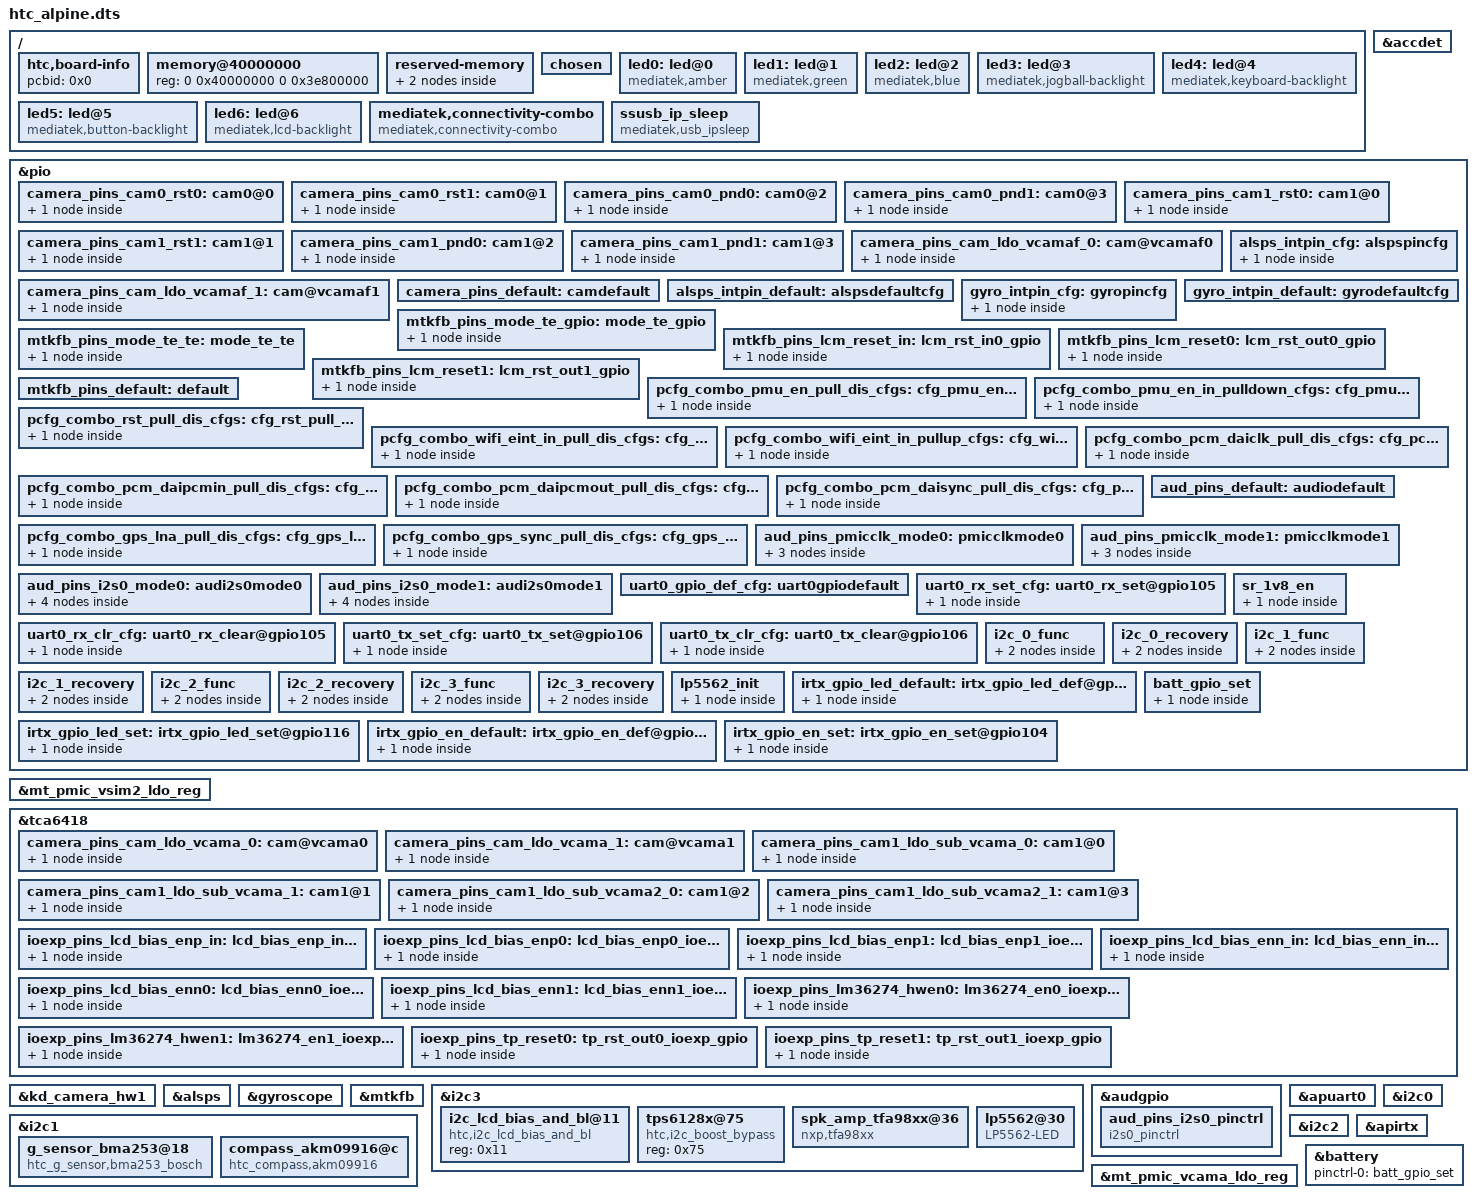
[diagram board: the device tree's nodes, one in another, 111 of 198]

/dts-v1/;

#include "mt6755.dtsi"
#include "htc_alpine/mt6755-ioexp-alpine.dtsi"
#include "htc_alpine/mt6755-usb-alpine.dtsi"
#include "htc_alpine/mt6755-key-alpine.dtsi"
#include "htc_alpine/mt6755-fp-alpine.dtsi"
#include "htc_alpine/mt6755-shub-alpine.dtsi"
#include "htc_alpine/mt6755-hallsensor-alpine-XA.dtsi"
#include "htc_alpine/mt6755-vibrator-alpine.dtsi"
#include "cust.dtsi"
#include "htc_features.dtsi"
#include "htc_alpine/mt6755-touch-alpine.dtsi"
#include "htc_alpine/mt6755-cap-alpine.dtsi"
#include "htc_alpine/mt6755-flashlight-alpine.dtsi"
#include "htc_alpine/cust_mt6755_msdc.dtsi"
#include "htc_alpine/mt6755-nfc-alpine.dtsi"
#include "htc_alpine/mt6755-audio-alpine.dtsi"

/ {
	htc,board-info {
		pcbid = <0x0>;
	};
	memory@40000000 {
		device_type = "memory";
		reg = <0 0x40000000 0 0x3e800000>;
	};
	reserved-memory {
		#address-cells = <2>;
		#size-cells = <2>;
		ranges;

		memory-ssvp-reserved-memory {
			compatible = "mediatek,memory-ssvp";
			size = <0 0x10000000>;
			alignment = <0 0x1000000>;
			alloc-ranges = <0 0x40000000 0 0xbf000000>;
		};

		reserve-memory-ccci_md3_ccif {
			compatible = "mediatek,reserve-memory-ccci_md3_ccif";
			no-map;
			size = <0 0x01000000>;
			alignment = <0 0x2000000>;
			alloc-ranges = <0 0x40000000 0 0xc0000000>;
		};
	};

	/* chosen */
	chosen {
		bootargs = "console=tty0 console=ttyMT0,921600n1 root=/dev/ram initrd=0x44000000,0x4B434E loglevel=8";

		/* fpga may has no lk, we need to specify display info here */
		/* fb buffer is reserved using this dts by memory node above */
		atag,videolfb-fb_base_h = <0x0>;
		atag,videolfb-fb_base_l = <0x7E800000>;
		atag,videolfb-islcmfound = <1>;
		/* because no lk, so lcm is not inited */
		atag,videolfb-islcm_inited = <0>;
		atag,videolfb-fps= <6000>;
		atag,videolfb-vramSize= <0x01800000>;
		atag,videolfb-lcmname= "nt35695_fhd_dsi_cmd_truly_nt50358_drv";
	};
	led0:led@0 {
		compatible = "mediatek,amber";
		led_mode = <3>;
		data = <2>;
		pwm_config = <0 0 0 0 0>;
	};
	led1:led@1 {
		compatible = "mediatek,green";
		led_mode = <3>;
		data = <1>;
		pwm_config = <0 0 0 0 0>;
	};
	led2:led@2 {
		compatible = "mediatek,blue";
		led_mode = <0>;
		data = <1>;
		pwm_config = <0 0 0 0 0>;
	};
	led3:led@3 {
		compatible = "mediatek,jogball-backlight";
		led_mode = <0>;
		data = <1>;
		pwm_config = <0 0 0 0 0>;
	};
	led4:led@4 {
		compatible = "mediatek,keyboard-backlight";
		led_mode = <0>;
		data = <1>;
		pwm_config = <0 0 0 0 0>;
	};
	led5:led@5 {
		compatible = "mediatek,button-backlight";
		led_mode = <0>;
		data = <1>;
		pwm_config = <0 0 0 0 0>;
	};
	led6:led@6 {
		compatible = "mediatek,lcd-backlight";
		/* MT65XX_LED_MODE_CUST_LCM */
		led_mode = <4>;
		data = <1>;
		pwm_config = <0 0 0 0 0>;
	};
	//vibrator0:vibrator@0 {
	//	compatible = "mediatek,vibrator";
	//	vib_timer = <25>;
	//	vib_limit = <9>;
	//	vib_vol= <6>;
	//};

	/*  start sensor */
	//cust_accel {
	//	compatible = "mediatek,mpu6515a";
	//	i2c_num	= <1>;
	//	/* i2c_addr = <0x4c 0 0 0>; */
	//	direction = <6>;
	//	power_id = <0xffff>;
	//	power_vol = <0>;
	//	firlen = <16>;
	//	is_batch_supported = <1>;
	//};

	//cust_alsps@0 {
	//	compatible		= "mediatek,cm36686";
	//	i2c_num			= <1>;
	//	i2c_addr		= <0x60 0 0 0>;
	//	polling_mode_ps		= <0>;
	//	polling_mode_als	= <1>;
	//	power_id		= <0xffff>;
	//	power_vol		= <0>;
	//	/* Total has 15 level*/
	//	als_level	= <0 257 637 1027 2297 5588 6730 11301 20449 25768 31122 45552 57937 57937 57937>;
	//	/*  Total has 16 range*/
	//	als_value	= <0 132 304 502 1004 2003 3006 5006 8004 10000 12000 16000 20000 20000 20000 20000>;
	//	ps_threshold_high	=  <70>;
	//	ps_threshold_low	=  <40>;
	//	is_batch_supported_ps	= <1>;
	//	is_batch_supported_als	= <1>;
	//};

	//cust_mag {
	//	compatible			= "mediatek,yamaha532";
	//	i2c_num				= <1>;
	//	/* i2c_addr			= <0x0d 0 0 0>; */
	//	direction			= <0>;
	//	power_id			= <0xffff>;
	//	power_vol			= <0>;
	//	/* is_batch_supported		= <0>; */
	//};

	//cust_gyro {
	//	compatible			= "mediatek,mpu6515g";
	//	i2c_num				= <1>;
	//	/* i2c_addr			= <0x68 0 0 0>; */
	//	direction			= <6>;
	//	power_id			= <0xffff>;
	//	power_vol			= <0>;
	//	firlen				= <0>;
	//	is_batch_supported		= <0>;
	//};

	//cust_baro {
	//	compatible			= "mediatek,bmp280new";
	//	i2c_num				= <1>;
	//	/* i2c_addr			= <0x68 0 0 0>; */
	//	direction			= <0>;
	//	power_id			= <0xffff>;
	//	power_vol			= <0>;
	//	firlen				= <32>;
	//	is_batch_supported		= <0>;
	//};
	///* end sensor */

	/* Connectivity */
	mediatek,connectivity-combo {
		compatible = "mediatek,connectivity-combo";
		/*gpio_combo_ldo_en_pin = <&pio 0xffff 0>;	/*0) GPIO_COMBO_LDO_EN_PIN */
		/*gpio_combo_pmuv28_en_pin = <&pio 0xffff 0>;	/* 1) GPIO_COMBO_PMUV28_EN_PIN */
		gpio_combo_pmu_en_pin = <&pio 22 0>;		/* 2) GPIO_COMBO_PMU_EN_PIN */
		gpio_combo_rst_pin = <&pio 21 0>;		/* 3) GPIO_COMBO_RST_PIN pin */
		/*gpio_combo_bgf_eint_pin = <&pio 0xffff 0>;	/* 4) GPIO_COMBO_BGF_EINT_PIN */
		gpio_wifi_eint_pin = <&pio 18 0>;		/* 5) GPIO_WIFI_EINT_PIN */
		/*gpio_all_eint_pin = <&pio 0xffff 0>;		/* 6) GPIO_ALL_EINT_PIN */
		/*gpio_combo_urxd_pin = <&pio 0xffff 0>;		/* 7) GPIO_COMBO_URXD_PIN */
		/*gpio_combo_utxd_pin = <&pio 0xffff 0>;		/* 8) GPIO_COMBO_UTXD_PIN */
		gpio_pcm_daiclk_pin = <&pio 14 0>;		/* 9) GPIO_PCM_DAICLK_PIN */
		gpio_pcm_daipcmin_pin = <&pio 16 0>;		/* 10) GPIO_PCM_DAIPCMIN_PIN */
		gpio_pcm_daipcmout_pin = <&pio 15 0>;		/* 11) GPIO_PCM_DAIPCMOUT_PIN */
		gpio_pcm_daisync_pin = <&pio 13 0>;		/* 12) GPIO_PCM_DAISYNC_PIN */
		/*gpio_combo_i2s_ck_pin = <&pio 0xffff 0>;	/* 13) GPIO_COMBO_I2S_CK_PIN */
		/*gpio_combo_i2s_ws_pin = <&pio 0xffff 0>;	/* 14) GPIO_COMBO_I2S_WS_PIN */
		/*gpio_combo_i2s_dat_pin = <&pio 0xffff 0>;	/* 15) GPIO_COMBO_I2S_DAT_PIN */
		gpio_gps_sync_pin = <&pio 121 0>;		/* 16) GPIO_GPS_SYNC_PIN */
		gpio_gps_lna_pin = <&pio 114 0>;		/* 17) GPIO_GPS_LNA_PIN is ext pin on 6397 */
		pinctrl-names = "gpio_pmu_en_pull_dis",
			"gpio_pmu_en_in_pulldown",
			"gpio_rst_pull_dis",
			"gpio_wifi_eint_in_pull_dis",
			"gpio_wifi_eint_in_pullup",
			"gpio_pcm_daiclk_pull_dis",
			"gpio_pcm_daipcmin_pull_dis",
			"gpio_pcm_daipcmout_pull_dis",
			"gpio_pcm_daisync_pull_dis",
			"gpio_gps_lna_pull_dis",
			"gpio_gps_sync_pull_dis";
		pinctrl-0 = <&pcfg_combo_pmu_en_pull_dis_cfgs>;
		pinctrl-1 = <&pcfg_combo_pmu_en_in_pulldown_cfgs>;
		pinctrl-2 = <&pcfg_combo_rst_pull_dis_cfgs>;
		pinctrl-3 = <&pcfg_combo_wifi_eint_in_pull_dis_cfgs>;
		pinctrl-4 = <&pcfg_combo_wifi_eint_in_pullup_cfgs>;
		pinctrl-5 = <&pcfg_combo_pcm_daiclk_pull_dis_cfgs>;
		pinctrl-6 = <&pcfg_combo_pcm_daipcmin_pull_dis_cfgs>;
		pinctrl-7 = <&pcfg_combo_pcm_daipcmout_pull_dis_cfgs>;
		pinctrl-8 = <&pcfg_combo_pcm_daisync_pull_dis_cfgs>;
		pinctrl-9 = <&pcfg_combo_gps_lna_pull_dis_cfgs>;
		pinctrl-10 = <&pcfg_combo_gps_sync_pull_dis_cfgs>;
		interrupt-parent = <&eintc>;
		interrupts = < 18 IRQ_TYPE_LEVEL_LOW >;	/* WIFI EINT num is 1 active low level-sensitive */
		debounce = <18 0>;
		status = "okay";
	};

	ssusb_ip_sleep {
		compatible = "mediatek,usb_ipsleep";
	};
};
&accdet {
		accdet-mic-vol = <7>;
		headset-mode-setting = <0x900 0x200 1 0x1F0 0x800 0x250 0x20>;
		accdet-plugout-debounce = <20>;
		/*1:ACC mode, 2:low cost without in bias, 6:low cost with in bias*/
		accdet-mic-mode = <2>;
		/*0--MD_MAX--UP_MAX--DW_MAX*/
		headset-three-key-threshold = <0 90 178 500>;
		/*0--MD_MAX--VOICE_MAX--UP_MAX--DW_MAX*/
		headset-four-key-threshold = <0 58 121 192 450>;
};

/* CAMERA GPIO standardization */
&pio {
	camera_pins_cam0_rst0: cam0@0 {
	    pins_cmd_dat {
			pins = <PINMUX_GPIO110__FUNC_GPIO110>;
			slew-rate = <1>; /*direction 0:in, 1:out*/
			output-low;/*direction out used only. output_low or high*/
		};
	};
	camera_pins_cam0_rst1: cam0@1 {
	    pins_cmd_dat {
			pins = <PINMUX_GPIO110__FUNC_GPIO110>;
			slew-rate = <1>;
			output-high;
		};
	};
	camera_pins_cam0_pnd0: cam0@2 {
	    pins_cmd_dat {
			pins = <PINMUX_GPIO107__FUNC_GPIO107>;
			slew-rate = <1>;
			output-low;
		};
	};
	camera_pins_cam0_pnd1: cam0@3 {
	    pins_cmd_dat {
			pins = <PINMUX_GPIO107__FUNC_GPIO107>;
			slew-rate = <1>;
			output-high;
		};
	};
	camera_pins_cam1_rst0: cam1@0 {
	    pins_cmd_dat {
			pins = <PINMUX_GPIO111__FUNC_GPIO111>;
			slew-rate = <1>; /*direction 0:in, 1:out*/
			output-low;/*direction out used only. output_low or high*/
		};
	};
	camera_pins_cam1_rst1: cam1@1 {
	    pins_cmd_dat {
			pins = <PINMUX_GPIO111__FUNC_GPIO111>;
			slew-rate = <1>;
			output-high;
		};
	};
	camera_pins_cam1_pnd0: cam1@2 {
	    pins_cmd_dat {
			pins = <PINMUX_GPIO108__FUNC_GPIO108>;
			slew-rate = <1>;
			output-low;
		};
	};
	camera_pins_cam1_pnd1: cam1@3 {
	    pins_cmd_dat {
			pins = <PINMUX_GPIO108__FUNC_GPIO108>;
			slew-rate = <1>;
			output-high;
		};
	};
	camera_pins_cam_ldo_vcamaf_0: cam@vcamaf0 {
	    pins_cmd_dat {
			pins = <PINMUX_GPIO111__FUNC_GPIO111>;
			slew-rate = <1>;
			output-low;
		};
	};
	camera_pins_cam_ldo_vcamaf_1: cam@vcamaf1 {
	    pins_cmd_dat {
			pins = <PINMUX_GPIO111__FUNC_GPIO111>;
			slew-rate = <1>;
			output-high;
		};
	};

	camera_pins_default: camdefault {
	};

};

/* HTC_START, Add regulator for some gpio power source */
&mt_pmic_vsim2_ldo_reg {
       regulator-name = "vsim2";
       regulator-default-on = <0>; /* 0:skip, 1: off, 2:on */
       status = "okay";
};
/* HTC_END */

&tca6418 {
	camera_pins_cam_ldo_vcama_0: cam@vcama0 {
		config {
			pins = "gpio4";
			output-low;
			bias-disable;
		};
	};

	camera_pins_cam_ldo_vcama_1: cam@vcama1 {
		config {
			pins = "gpio4";
			output-high;
			bias-disable;
		};
	};

	camera_pins_cam1_ldo_sub_vcama_0: cam1@0 {
	    config {
			pins = "gpio3";
			output-low;
			bias-disable;
		};
	};

	camera_pins_cam1_ldo_sub_vcama_1: cam1@1 {
	    config {
			pins = "gpio3";
			output-high;
			bias-disable;
		};
	};

	camera_pins_cam1_ldo_sub_vcama2_0: cam1@2 {
	    config {
			pins = "gpio2";
			output-low;
			bias-disable;
		};
	};

	camera_pins_cam1_ldo_sub_vcama2_1: cam1@3 {
	    config {
			pins = "gpio2";
			output-high;
			bias-disable;
		};
	};
};


&kd_camera_hw1 {
	pinctrl-names = "default",
			"cam0_rst0", "cam0_rst1", "cam0_pnd0", "cam0_pnd1",
			"cam1_rst0", "cam1_rst1", "cam1_pnd0", "cam1_pnd1",
			/*"cam2_rst0", "cam2_rst1", "cam2_pnd0", "cam2_pnd1",*/
			"cam_ldo_vcama_0", "cam_ldo_vcama_1", "cam_ldo_vcamaf_0", "cam_ldo_vcamaf_1",
                        "cam1_ldo_sub_vcama_0", "cam1_ldo_sub_vcama_1",
                        "cam1_ldo_sub_vcama2_0", "cam1_ldo_sub_vcama2_1";
	pinctrl-0 = <&camera_pins_default>;
	pinctrl-1 = <&camera_pins_cam0_rst0>;
	pinctrl-2 = <&camera_pins_cam0_rst1>;
	pinctrl-3 = <&camera_pins_cam0_pnd0>;
	pinctrl-4 = <&camera_pins_cam0_pnd1>;
	pinctrl-5 = <&camera_pins_cam1_rst0>;
	pinctrl-6 = <&camera_pins_cam1_rst1>;
	pinctrl-7 = <&camera_pins_cam1_pnd0>;
	pinctrl-8 = <&camera_pins_cam1_pnd1>;
	/* for main2 */
	/*pinctrl-9 = <&camera_pins_cam2_rst0>;
	pinctrl-10 = <&camera_pins_cam2_rst1>;
	pinctrl-11 = <&camera_pins_cam2_pnd0>;
	pinctrl-12 = <&camera_pins_cam2_pnd1>;*/
	/* for ldo control by gpio */
	/*pinctrl-13 = <&camera_pins_cam_ldo_vcama_0>;
	pinctrl-14 = <&camera_pins_cam_ldo_vcama_1>;*/
	pinctrl-9 = <&camera_pins_cam_ldo_vcama_0>;
	pinctrl-10 = <&camera_pins_cam_ldo_vcama_1>;
	pinctrl-11 = <&camera_pins_cam_ldo_vcamaf_0>;
	pinctrl-12 = <&camera_pins_cam_ldo_vcamaf_1>;
	pinctrl-13 = <&camera_pins_cam1_ldo_sub_vcama_0>;
	pinctrl-14 = <&camera_pins_cam1_ldo_sub_vcama_1>;
	pinctrl-15 = <&camera_pins_cam1_ldo_sub_vcama2_0>;
	pinctrl-16 = <&camera_pins_cam1_ldo_sub_vcama2_1>;

	vcam_sub_sim2-supply = <&mt_pmic_vsim2_ldo_reg>;
	vcam_camaf-supply = <&mt_pmic_vldo28_ldo_reg>;
	vcam_cama-supply = <&mt_pmic_vcama_ldo_reg>;
	status = "okay";

};
/* CAMERA GPIO end */

&pio {
	alsps_intpin_cfg: alspspincfg {

		pins_cmd_dat {
			pins = <PINMUX_GPIO6__FUNC_GPIO6>;
			slew-rate = <0>;
			bias-pull-up = <00>;
		};
	};

	alsps_intpin_default: alspsdefaultcfg {

	};

	gyro_intpin_cfg: gyropincfg {

		pins_cmd_dat {
			pins = <PINMUX_GPIO4__FUNC_GPIO4>;
			slew-rate = <0>;
			bias-pull-down = <00>;
		};
	};

	gyro_intpin_default: gyrodefaultcfg {

	};
};

&alsps {
	pinctrl-names = "pin_default", "pin_cfg";
	pinctrl-0 = <&alsps_intpin_default>;
	pinctrl-1 = <&alsps_intpin_cfg>;
	status = "okay";
};

&gyroscope {
	pinctrl-names = "pin_default", "pin_cfg";
	pinctrl-0 = <&gyro_intpin_default>;
	pinctrl-1 = <&gyro_intpin_cfg>;
	status = "okay";
};

/* DISPSYS GPIO standardization */
&pio {
	mtkfb_pins_mode_te_gpio: mode_te_gpio {
		pins_cmd_dat {
			pins = <PINMUX_GPIO44__FUNC_GPIO44>;
		};
	};

	mtkfb_pins_mode_te_te: mode_te_te {
		pins_cmd_dat {
			pins = <PINMUX_GPIO44__FUNC_DSI_TE>;
		};
	};

	mtkfb_pins_lcm_reset_in: lcm_rst_in0_gpio {
		pins_cmd_dat {
			pins = <PINMUX_GPIO158__FUNC_GPIO158>;
			/* set to input for sensorhub usage when suspend */
			slew-rate = <0>;
			bias-pull-down;
		};
	};

	mtkfb_pins_lcm_reset0: lcm_rst_out0_gpio {
		pins_cmd_dat {
			pins = <PINMUX_GPIO158__FUNC_GPIO158>;
			slew-rate = <1>;
			output-low;
		};
	};

	mtkfb_pins_lcm_reset1: lcm_rst_out1_gpio {
		pins_cmd_dat {
			pins = <PINMUX_GPIO158__FUNC_GPIO158>;
			slew-rate = <1>;
			output-high;
		};
	};

	mtkfb_pins_default: default {
	};
};

&tca6418 {
	ioexp_pins_lcd_bias_enp_in: lcd_bias_enp_in_ioexp_gpio {
		config {
			pins = "gpio8";
			/* set to input for sensorhub usage when suspend */
			input-enable;
			bias-pull-down;
		};
	};

	ioexp_pins_lcd_bias_enp0: lcd_bias_enp0_ioexp_gpio {
		config {
			pins = "gpio8";
			output-low;
			bias-disable;
		};
	};

	ioexp_pins_lcd_bias_enp1: lcd_bias_enp1_ioexp_gpio {
		config {
			pins = "gpio8";
			output-high;
			bias-disable;
		};
	};

	ioexp_pins_lcd_bias_enn_in: lcd_bias_enn_in_ioexp_gpio {
		config {
			pins = "gpio9";
			/* set to input for sensorhub usage when suspend */
			input-enable;
			bias-pull-down;
		};
	};

	ioexp_pins_lcd_bias_enn0: lcd_bias_enn0_ioexp_gpio {
		config {
			pins = "gpio9";
			output-low;
			bias-disable;
		};
	};

	ioexp_pins_lcd_bias_enn1: lcd_bias_enn1_ioexp_gpio {
		config {
			pins = "gpio9";
			output-high;
			bias-disable;
		};
	};

	ioexp_pins_lm36274_hwen0: lm36274_en0_ioexp_gpio {
		config {
			pins = "gpio14";
			output-low;
			bias-disable;
		};
	};

	ioexp_pins_lm36274_hwen1: lm36274_en1_ioexp_gpio {
		config {
			pins = "gpio14";
			output-high;
			bias-disable;
		};
	};

	ioexp_pins_tp_reset0: tp_rst_out0_ioexp_gpio {
		config {
			pins = "gpio15";
			output-low;
			bias-disable;
		};
	};

	ioexp_pins_tp_reset1: tp_rst_out1_ioexp_gpio {
		config {
			pins = "gpio15";
			output-high;
			bias-disable;
		};
	};
};

&mtkfb {
	pinctrl-names = "default",
	"mode_te_gpio", "mode_te_te",
	"lcm_rst_out0_gpio", "lcm_rst_out1_gpio",
	"lcm_rst_in0_gpio",
	"lcd_bias_enp0_ioexp_gpio", "lcd_bias_enp1_ioexp_gpio",
	"lcd_bias_enp_in_ioexp_gpio",
	"lcd_bias_enn0_ioexp_gpio", "lcd_bias_enn1_ioexp_gpio",
	"lcd_bias_enn_in_ioexp_gpio",
	"lm36274_en0_ioexp_gpio", "lm36274_en1_ioexp_gpio",
	"tp_rst_out0_ioexp_gpio", "tp_rst_out1_ioexp_gpio";
	pinctrl-0 = <&mtkfb_pins_default>;
	pinctrl-1 = <&mtkfb_pins_mode_te_gpio>;
	pinctrl-2 = <&mtkfb_pins_mode_te_te>;
	pinctrl-3 = <&mtkfb_pins_lcm_reset0>;
	pinctrl-4 = <&mtkfb_pins_lcm_reset1>;
	pinctrl-5 = <&mtkfb_pins_lcm_reset_in>;
	pinctrl-6 = <&ioexp_pins_lcd_bias_enp0>;
	pinctrl-7 = <&ioexp_pins_lcd_bias_enp1>;
	pinctrl-8 = <&ioexp_pins_lcd_bias_enp_in>;
	pinctrl-9 = <&ioexp_pins_lcd_bias_enn0>;
	pinctrl-10 = <&ioexp_pins_lcd_bias_enn1>;
	pinctrl-11 = <&ioexp_pins_lcd_bias_enn_in>;
	pinctrl-12 = <&ioexp_pins_lm36274_hwen0>;
	pinctrl-13 = <&ioexp_pins_lm36274_hwen1>;
	pinctrl-14 = <&ioexp_pins_tp_reset0>;
	pinctrl-15 = <&ioexp_pins_tp_reset1>;
	status = "okay";
};

&i2c3 {
	/* lm36274 */
	i2c_lcd_bias_and_bl@11 {
		compatible = "htc,i2c_lcd_bias_and_bl";
		reg = <0x11>;
	};

	tps6128x@75 {
		compatible = "htc,i2c_boost_bypass";
		reg = <0x75>;
	};
};
/* DISPSYS GPIO standardization end */

/* Connectivity GPIO standardization */
 &pio {
	pcfg_combo_pmu_en_pull_dis_cfgs:cfg_pmu_en_pull_dis {
		combo_pins {
			pins = <PINMUX_GPIO22__FUNC_GPIO22>;
			bias-disable;
		};
	};

	pcfg_combo_pmu_en_in_pulldown_cfgs:cfg_pmu_en_in_pulldown {
		combo_pins {
			pins = <PINMUX_GPIO22__FUNC_GPIO22>;
			bias-pull-down;
		};
	};

	pcfg_combo_rst_pull_dis_cfgs:cfg_rst_pull_dis {
		combo_pins {
			pins = <PINMUX_GPIO21__FUNC_GPIO21>;
			bias-disable;
		};
	};

	pcfg_combo_wifi_eint_in_pull_dis_cfgs:cfg_wifi_eint_in_pull_dis {
		combo_pins {
			pins = <PINMUX_GPIO18__FUNC_GPIO18>;
			slew-rate = <0>;
			bias-disable;
		};
	};

	pcfg_combo_wifi_eint_in_pullup_cfgs:cfg_wifi_eint_in_pullup {
		combo_pins {
			pins = <PINMUX_GPIO18__FUNC_GPIO18>;
			slew-rate = <0>;
			bias-pull-up = <00>;
		};
	};

	pcfg_combo_pcm_daiclk_pull_dis_cfgs:cfg_pcm_daiclk_pull_dis {
		combo_pins {
			pins = <PINMUX_GPIO14__FUNC_MRG_CLK>;
			bias-disable;
		};
	};

	pcfg_combo_pcm_daipcmin_pull_dis_cfgs:cfg_pcm_daipcmin_pull_dis {
		combo_pins {
			pins = <PINMUX_GPIO16__FUNC_MRG_DI>;
			bias-disable;
		};
	};

	pcfg_combo_pcm_daipcmout_pull_dis_cfgs:cfg_pcm_daipcmout_pull_dis {
		combo_pins {
			pins = <PINMUX_GPIO15__FUNC_MRG_DO>;
			bias-disable;
		};
	};

	pcfg_combo_pcm_daisync_pull_dis_cfgs:cfg_pcm_daisync_pull_dis {
		combo_pins {
			pins = <PINMUX_GPIO13__FUNC_MRG_SYNC>;
			bias-disable;
		};
	};

	pcfg_combo_gps_lna_pull_dis_cfgs:cfg_gps_lna_pull_dis {
		combo_pins {
			pins = <PINMUX_GPIO114__FUNC_GPIO114>;
			bias-disable;
		};
	};

	pcfg_combo_gps_sync_pull_dis_cfgs:cfg_gps_sync_pull_dis {
		combo_pins {
			pins = <PINMUX_GPIO121__FUNC_AGPS_SYNC>;
			bias-disable;
		};
	};
 };
/* Connectivity end */

/* AUDIO GPIO standardization */
/* HTC_AUD_START */
/*
&audgpio {
	pinctrl-names = "default", "audpmicclk-mode0", "audpmicclk-mode1",
		"audi2s1-mode0", "audi2s1-mode1", "extamp-pullhigh", "extamp-pulllow",
		"extamp2-pullhigh", "extamp2-pulllow", "rcvspk-pullhigh",
		"rcvspk-pulllow","hpdepop-pullhigh","hpdepop-pulllow";
	pinctrl-0 = <&aud_pins_default>;
	pinctrl-1 = <&aud_pins_pmicclk_mode0>;
	pinctrl-2 = <&aud_pins_pmicclk_mode1>;
	pinctrl-3 = <&aud_pins_i2s1_mode0>;
	pinctrl-4 = <&aud_pins_i2s1_mode1>;
	pinctrl-5 = <&aud_pins_extamp_high>;
	pinctrl-6 = <&aud_pins_extamp_low>;
	pinctrl-7 = <&aud_pins_extamp2_high>;
	pinctrl-8 = <&aud_pins_extamp2_low>;
	pinctrl-9 = <&aud_pins_rcvspk_high>;
	pinctrl-10 = <&aud_pins_rcvspk_low>;
	pinctrl-11 = <&aud_pins_hpdepop_high>;
	pinctrl-12 = <&aud_pins_hpdepop_low>;
	status = "okay";
};
*/
&audgpio {
	pinctrl-names = "default", "audpmicclk-mode0", "audpmicclk-mode1";
	pinctrl-0 = <&aud_pins_default>;
	pinctrl-1 = <&aud_pins_pmicclk_mode0>;
	pinctrl-2 = <&aud_pins_pmicclk_mode1>;
	status = "okay";
	aud_pins_i2s0_pinctrl {
		compatible = "i2s0_pinctrl";
		pinctrl-names = "audi2s0-mode0",
				"audi2s0-mode1";
		pinctrl-0 = <&aud_pins_i2s0_mode0>;
		pinctrl-1 = <&aud_pins_i2s0_mode1>;
		status = "okay";
	};
};
/* HTC_AUD_END */

&pio {
	aud_pins_default: audiodefault {
	};

	aud_pins_pmicclk_mode0: pmicclkmode0 {
		pins_cmd0_dat {
			pins = <PINMUX_GPIO149__FUNC_GPIO149>;
			/* HTC_AUD_START */
			slew-rate = <0>;
			bias-pull-down = <00>;
			/* HTC_AUD_END */
		};
		pins_cmd1_dat {
			pins = <PINMUX_GPIO150__FUNC_GPIO150>;
			slew-rate = <0>;
			/* HTC_AUD_START */
			bias-pull-down = <00>;
			/* HTC_AUD_END */
		};
		pins_cmd2_dat {
			pins = <PINMUX_GPIO151__FUNC_GPIO151>;
			/* HTC_AUD_START */
			slew-rate = <0>;
			bias-pull-down = <00>;
			/* HTC_AUD_END */
		};
	};

	aud_pins_pmicclk_mode1: pmicclkmode1 {
		pins_cmd0_dat {
			pins = <PINMUX_GPIO149__FUNC_AUD_CLK_MOSI>;
		};
		pins_cmd1_dat {
			pins = <PINMUX_GPIO150__FUNC_AUD_DAT_MOSI>;
		};
		pins_cmd2_dat {
			pins = <PINMUX_GPIO151__FUNC_AUD_DAT_MISO>;
		};
	};

/* HTC_AUD_START */
	aud_pins_i2s0_mode0: audi2s0mode0 {
		pins_cmd0_dat {
			pins = <PINMUX_GPIO7__FUNC_GPIO7>;
		};
		pins_cmd1_dat {
			pins = <PINMUX_GPIO26__FUNC_GPIO26>;
		};
		pins_cmd2_dat {
			pins = <PINMUX_GPIO27__FUNC_GPIO27>;
		};
		pins_cmd3_dat {
			pins = <PINMUX_GPIO28__FUNC_GPIO28>;
		};
	};

	aud_pins_i2s0_mode1: audi2s0mode1 {
		pins_cmd0_dat {
			pins = <PINMUX_GPIO7__FUNC_I2S0_DI>;
		};
		pins_cmd1_dat {
			pins = <PINMUX_GPIO26__FUNC_I2S3_BCK>;
		};
		pins_cmd2_dat {
			pins = <PINMUX_GPIO27__FUNC_I2S3_LRCK>;
		};
		pins_cmd3_dat {
			pins = <PINMUX_GPIO28__FUNC_I2S3_DO>;
		};
	};
    /*
	aud_pins_i2s1_mode0: audi2s1mode0 {
		pins_cmd0_dat {
			pins = <PINMUX_GPIO7__FUNC_GPIO7>;
		};
		pins_cmd1_dat {
			pins = <PINMUX_GPIO6__FUNC_GPIO6>;
		};
		pins_cmd2_dat {
			pins = <PINMUX_GPIO5__FUNC_GPIO5>;
		};
	};

	aud_pins_i2s1_mode1: audi2s1mode1 {
		pins_cmd0_dat {
			pins = <PINMUX_GPIO7__FUNC_I2S0_DI>;
		};
		pins_cmd1_dat {
			pins = <PINMUX_GPIO6__FUNC_I2S0_LRCK>;
		};
		pins_cmd2_dat {
			pins = <PINMUX_GPIO5__FUNC_I2S0_BCK>;
		};
	};

	aud_pins_extamp_high: audexamphigh {
		pins_cmd_dat {
			pins = <PINMUX_GPIO115__FUNC_GPIO115>;
			slew-rate = <1>;
			output-high;
		};
	};

	aud_pins_extamp_low: audexamplow {
		pins_cmd_dat {
			pins = <PINMUX_GPIO115__FUNC_GPIO115>;
			slew-rate = <1>;
			output-low;
		};
	};

	aud_pins_extamp2_high: audexam2phigh {
		pins_cmd_dat {
			pins = <PINMUX_GPIO54__FUNC_GPIO54>;
			slew-rate = <1>;
			output-high;
		};
	};
	aud_pins_extamp2_low: audexamp2low {
		pins_cmd_dat {
			pins = <PINMUX_GPIO54__FUNC_GPIO54>;
			slew-rate = <1>;
			output-low;
		};
	};

	aud_pins_rcvspk_high: audrcvspkhigh {
		pins_cmd_dat {
			pins = <PINMUX_GPIO120__FUNC_GPIO120>;
			slew-rate = <1>;
			output-high;
		};
	};

	aud_pins_rcvspk_low: audrcvspklow {
		pins_cmd_dat {
			pins = <PINMUX_GPIO120__FUNC_GPIO120>;
			slew-rate = <1>;
			output-low;
		};
	};

	aud_pins_hpdepop_high: audhpdepophigh {
		pins_cmd_dat {
			pins = <PINMUX_GPIO24__FUNC_GPIO24>;
			slew-rate = <1>;
			output-high;
		};
	};

	aud_pins_hpdepop_low: audhpdepoplow {
		pins_cmd_dat {
			pins = <PINMUX_GPIO24__FUNC_GPIO24>;
			slew-rate = <1>;
			output-low;
		};
	};
	*/
/* HTC_AUD_END */
};
/* AUDIO GPIO end */

/* HTC_AUD_START */
&i2c3 {
	spk_amp_tfa98xx@36 {
		compatible = "nxp,tfa98xx";
		reg = <0x36>;
		reset-gpio = <90>;
		i2c-speed = <400>;	/* KHz */
	};
};
/* HTC_AUD_END */

/* UART GPIO */
&apuart0 {
	pinctrl-names = "uart0_gpio_default",
			"uart0_rx_set",
			"uart0_rx_clear",
			"uart0_tx_set",
			"uart0_tx_clear";
	pinctrl-0 = <&uart0_gpio_def_cfg>;
	pinctrl-1 = <&uart0_rx_set_cfg>;
	pinctrl-2 = <&uart0_rx_clr_cfg>;
	pinctrl-3 = <&uart0_tx_set_cfg>;
	pinctrl-4 = <&uart0_tx_clr_cfg>;
	status = "okay";
};

&pio {
	/* UART GPIO Settings - Start */
	/* UART0: rx set, rx clear, tx clear, tx clear*/
	uart0_gpio_def_cfg:uart0gpiodefault {

	};
	uart0_rx_set_cfg:uart0_rx_set@gpio105 {
		pins_cmd_dat {
			pins = <PINMUX_GPIO105__FUNC_URXD0>;
		};
	};
	uart0_rx_clr_cfg:uart0_rx_clear@gpio105  {
		pins_cmd_dat {
			pins = <PINMUX_GPIO105__FUNC_GPIO105>;
			slew-rate = <1>;
			output-high;
		};
	};
	uart0_tx_set_cfg:uart0_tx_set@gpio106  {
		pins_cmd_dat {
			pins = <PINMUX_GPIO106__FUNC_UTXD0>;
		};
	};
	uart0_tx_clr_cfg:uart0_tx_clear@gpio106  {
		pins_cmd_dat {
			pins = <PINMUX_GPIO106__FUNC_GPIO106>;
			slew-rate = <1>;
			output-high;
		};
	};
};/* UART GPIO end */

&pio {
	sr_1v8_en: sr_1v8_en {
		pins_cmd_dat {
			pins = <PINMUX_GPIO8__FUNC_GPIO8>;
			slew-rate = <1>;
			output-high;
		};
	};
};

/* I2C start */
&pio {
	i2c_0_func: i2c_0_func {
		pins_cmd0_dat {
			pins = <PINMUX_GPIO92__FUNC_SDA0>;
			slew-rate = <0>;

			bias-pull-down = <00>;
			output-low;
			input-schmitt-enable = <0>;
		};
		pins_cmd1_dat {
			pins = <PINMUX_GPIO93__FUNC_SCL0>;
			slew-rate = <0>;

			bias-pull-down = <00>;
			output-low;
			input-schmitt-enable = <0>;
		};
	};

	i2c_0_recovery: i2c_0_recovery {
		pins_cmd0_dat {
			pins = <PINMUX_GPIO92__FUNC_GPIO92>;
			slew-rate = <0>;
			bias-disable;
		};
		pins_cmd1_dat {
			pins = <PINMUX_GPIO93__FUNC_GPIO93>;
			slew-rate = <0>;
			bias-disable;
		};
	};

	i2c_1_func: i2c_1_func {
		pins_cmd0_dat {
			pins = <PINMUX_GPIO91__FUNC_SDA1>;
			slew-rate = <0>;

			bias-pull-down = <00>;
			output-low;
			input-schmitt-enable = <0>;
		};
		pins_cmd1_dat {
			pins = <PINMUX_GPIO94__FUNC_SCL1>;
			slew-rate = <0>;

			bias-pull-down = <00>;
			output-low;
			input-schmitt-enable = <0>;
		};
	};

	i2c_1_recovery: i2c_1_recovery {
		pins_cmd0_dat {
			pins = <PINMUX_GPIO91__FUNC_GPIO91>;
			slew-rate = <0>;
			bias-disable;
		};
		pins_cmd1_dat {
			pins = <PINMUX_GPIO94__FUNC_GPIO94>;
			slew-rate = <0>;
			bias-disable;
		};
	};

	i2c_2_func: i2c_2_func {
		pins_cmd0_dat {
			pins = <PINMUX_GPIO113__FUNC_SDA2>;
			slew-rate = <0>;

			bias-pull-down = <00>;
			output-low;
			input-schmitt-enable = <0>;
		};
		pins_cmd1_dat {
			pins = <PINMUX_GPIO112__FUNC_SCL2>;
			slew-rate = <0>;

			bias-pull-down = <00>;
			output-low;
			input-schmitt-enable = <0>;
		};
	};

	i2c_2_recovery: i2c_2_recovery {
		pins_cmd0_dat {
			pins = <PINMUX_GPIO113__FUNC_GPIO113>;
			slew-rate = <0>;
			bias-disable;
		};
		pins_cmd1_dat {
			pins = <PINMUX_GPIO112__FUNC_GPIO112>;
			slew-rate = <0>;
			bias-disable;
		};
	};

	i2c_3_func: i2c_3_func {
		pins_cmd0_dat {
			pins = <PINMUX_GPIO50__FUNC_SDA3>;
			slew-rate = <0>;

			bias-pull-down = <00>;
			output-low;
			input-schmitt-enable = <0>;
		};
		pins_cmd1_dat {
			pins = <PINMUX_GPIO49__FUNC_SCL3>;
			slew-rate = <0>;

			bias-pull-down = <00>;
			output-low;
			input-schmitt-enable = <0>;
		};
	};

	i2c_3_recovery: i2c_3_recovery {
		pins_cmd0_dat {
			pins = <PINMUX_GPIO50__FUNC_GPIO50>;
			slew-rate = <0>;
			bias-disable;
		};
		pins_cmd1_dat {
			pins = <PINMUX_GPIO49__FUNC_GPIO49>;
			slew-rate = <0>;
			bias-disable;
		};
	};

};
/* I2C end */

&i2c0 {
	recover_clk_cnt = <17>;
	pinctrl-names = "i2c_func", "i2c_recovery";
	pinctrl-0 = <&i2c_0_func>;
	pinctrl-1 = <&i2c_0_recovery>;
	sda-gpio = <92>;
	scl-gpio = <93>;
};

&i2c1 {
	recover_clk_cnt = <17>;
	pinctrl-names = "i2c_func", "i2c_recovery";
	pinctrl-0 = <&i2c_1_func>;
	pinctrl-1 = <&i2c_1_recovery>;
	sda-gpio = <91>;
	scl-gpio = <94>;

	g_sensor_bma253@18 {
		compatible = "htc_g_sensor,bma253_bosch";
		reg = <0x18>;
		g_sensor_bma253,intr        = <10>;
		g_sensor_bma253,chip_layout = <4>;
		g_sensor_bma253,axis_map_x  = <0>;
		g_sensor_bma253,axis_map_y  = <1>;
		g_sensor_bma253,axis_map_z  = <2>;
		g_sensor_bma253,negate_x    = <0>;
		g_sensor_bma253,negate_y    = <0>;
		g_sensor_bma253,negate_z    = <0>;
	};

	compass_akm09916@c {
		compatible = "htc_compass,akm09916";
		reg = <0xc>;
		compass_akm09916,layout     = <6>;
		compass_akm09916,gpio_RSTN  = <13>;
	};
};


&i2c2 {
	recover_clk_cnt = <17>;
	pinctrl-names = "i2c_func", "i2c_recovery";
	pinctrl-0 = <&i2c_2_func>;
	pinctrl-1 = <&i2c_2_recovery>;
	sda-gpio = <113>;
	scl-gpio = <112>;
};

&i2c3 {
	recover_clk_cnt = <17>;
	pinctrl-names = "i2c_func", "i2c_recovery";
	pinctrl-0 = <&i2c_3_func>;
	pinctrl-1 = <&i2c_3_recovery>;
	sda-gpio = <50>;
	scl-gpio = <49>;
};


&mt_pmic_vcama_ldo_reg {
	/*regulator-always-on;*/
};

&i2c3 {
	lp5562@30 {
			compatible = "LP5562-LED";
			reg = <0x30>;
			lp5562,lp5562_en = <99>;
			lp5562,num_leds = <2>;
			pinctrl-names = "lp5562_init";
			pinctrl-0 = <&lp5562_init>;
			lp5562,current_param = <75>;
			lp5562,vk_current_param = <200>;
			vk-pwm-array = [00 10 10 10 1E 1E 1E 1E 1E 3C 84 84 FF FF FF FF];
			vk-black-cg-id-def = "DEF00", "GRY00", "LOB00", "BLK00";
			vk-black-cg-id-sec = "LEB00";
			vk-white-cg-id-def = "PNK00", "GOD00", "LOW00", "WHT00";
			vk-white-cg-id-sec = "LEW00";
			vk-black-pwm-array-def =     [00 10 10 10 1E 1E 1E 1E 1E 3C 84 84 FF FF FF FF];//brightness
			vk-white-pwm-array-def =     [00 10 10 10 1E 1E 1E 1E 1E 3C 84 84 FF FF FF FF];
			vk-black-current-array-def = [64 64 64 64 64 64 64 C8 C8 C8 C8 C8 C8 C8 C8 C8];//0.1 mA one step
			vk-white-current-array-def = [64 64 64 64 64 64 64 C8 C8 C8 C8 C8 C8 C8 C8 C8];
			vk-black-pwm-array-sec =     [00 10 10 10 1E 1E 1E 1E 1E 3C 84 84 FF FF FF FF];
			vk-white-pwm-array-sec =     [00 10 10 10 1E 1E 1E 1E 1E 3C 84 84 FF FF FF FF];
			vk-black-current-array-sec = [64 64 64 64 64 64 64 C8 C8 C8 C8 C8 C8 C8 C8 C8];
			vk-white-current-array-sec = [64 64 64 64 64 64 64 C8 C8 C8 C8 C8 C8 C8 C8 C8];
	};
};

&pio {
	lp5562_init: lp5562_init {
		pins_cmd_dat {
			pins = <PINMUX_GPIO99__FUNC_GPIO99>;
			slew-rate = <1>;
			bias-disable;
			output-high;
		};
	};
};

/* IRTX GPIO end */

&apirtx {
	pinctrl-names = "irtx_gpio_led_default",
			"irtx_gpio_led_set",
			"irtx_gpio_en_default",
			"irtx_gpio_en_set";

	pinctrl-0 = <&irtx_gpio_led_default>;
	pinctrl-1 = <&irtx_gpio_led_set>;
	pinctrl-2 = <&irtx_gpio_en_default>;
	pinctrl-3 = <&irtx_gpio_en_set>;
	status = "okay";
};
&pio {
	/* IRTX GPIO Settings -Start */
	/* default: GPIO0, output, high */
	irtx_gpio_led_default:irtx_gpio_led_def@gpio116 {
		pins_cmd_dat {
			pins = <PINMUX_GPIO116__FUNC_GPIO116>;
			slew-rate = <1>;
			bias-disable;
			output-low;
			input-schmitt-enable = <0>;
		};
	};

	irtx_gpio_led_set:irtx_gpio_led_set@gpio116 {
		pins_cmd_dat {
			pins = <PINMUX_GPIO116__FUNC_IRTX_OUT>;
			slew-rate = <1>;
			output-high;
		};
	};

	irtx_gpio_en_default:irtx_gpio_en_def@gpio104 {
		pins_cmd_dat {
			pins = <PINMUX_GPIO104__FUNC_GPIO104>;
			slew-rate = <1>;
			bias-disable;
			output-low;
			input-schmitt-enable = <0>;
		};
	};

	irtx_gpio_en_set:irtx_gpio_en_set@gpio104 {
		pins_cmd_dat {
			pins = <PINMUX_GPIO104__FUNC_GPIO104>;
			slew-rate = <1>;
			output-high;
		};
	};


}; /* IRTX GPIO Settings -End */

&battery {
	pinctrl-names = "batt_gpio_set";
	pinctrl-0 = <&batt_gpio_set>;
};

&pio {
	batt_gpio_set: batt_gpio_set {
		pins_cmd_dat {
			pins = <PINMUX_GPIO23__FUNC_GPIO23>;
			slew-rate = <0>;
			bias-disable;
		};
	};
};





